# CM41x_M4 register map
Vendor: Analog Devices; Series: CM41x_M4; File version: 1p0
CPU: CM4 r0p1, little endian, MPU, FPU, 4 interrupt priority bits
Registers are 32-bit, read-write, reset 0x0 unless marked. A register's access mark holds for its fields unless they carry their own. Offsets are from the block's base; [hi:lo] are bit positions.

## MATH0 — Math Unit Function
Base 0xF8009000
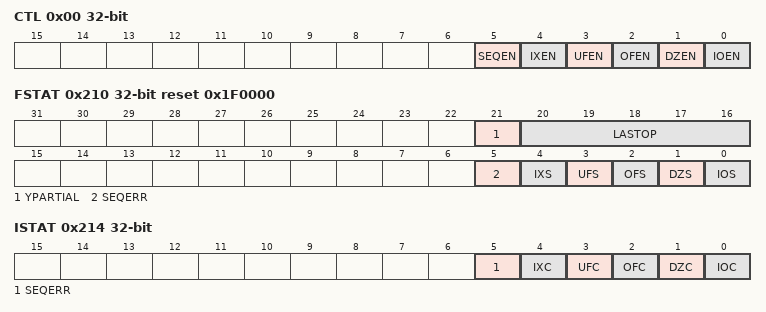
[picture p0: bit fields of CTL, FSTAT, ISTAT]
0x00 CTL — Math Unit Interrupt Enable Control
  [5] SEQEN range 0x00000000..0x00000001 — Interrupt Enable, Sequence Error
  [4] IXEN range 0x00000000..0x00000001 — Interrupt Enable, Inexact Operation
  [3] UFEN range 0x00000000..0x00000001 — Interrupt Enable, Underflow
  [2] OFEN range 0x00000000..0x00000001 — Interrupt Enable, Overflow
  [1] DZEN range 0x00000000..0x00000001 — Interrupt Enable, Divided By Zero
  [0] IOEN range 0x00000000..0x00000001 — Interrupt Enable, Invalid Operation
0x04 EXPF — exp(x) Function Register
  [31:0] DATA range 0x00000000..0xFFFFFFFF — Input Register X
0x0C EXP2F — exp2(x) Function Register
  [31:0] DATA range 0x00000000..0xFFFFFFFF — Input Register X
0x14 RECIPF — Reciprocal(x) or 1/x Function Register
  [31:0] DATA range 0x00000000..0xFFFFFFFF — Input Register X
0x1C SQRTF — Square Root or sqrt(x) Function
  [31:0] DATA range 0x00000000..0xFFFFFFFF — Input Register X
0x24 LNF — ln(x) Function Register
  [31:0] DATA range 0x00000000..0xFFFFFFFF — Input Register X
0x2C LOG2F — log2(x) Function Register
  [31:0] DATA range 0x00000000..0xFFFFFFFF — Input Register X
0x34 SINF — sin(x) Function Register
  [31:0] DATA range 0x00000000..0xFFFFFFFF — Input Register X
0x3C COSF — cos(x) Function Register
  [31:0] DATA range 0x00000000..0xFFFFFFFF — Input Register X
0x44 TANF — tan(x) Function Register
  [31:0] DATA range 0x00000000..0xFFFFFFFF — Input Register X
0x4C ASINF — arcsin(x) Function Register
  [31:0] DATA range 0x00000000..0xFFFFFFFF — Input Register X
0x54 ACOSF — arccos(x) Function Register
  [31:0] DATA range 0x00000000..0xFFFFFFFF — Input Register X
0x5C ATANF — arctan(x) Function Register
  [31:0] DATA range 0x00000000..0xFFFFFFFF — Input Register X
0x80 ATAN2F_Y — arctan(y/x) Function y Operand Register
  [31:0] DATA range 0x00000000..0xFFFFFFFF — Input Register Y
0x84 ATAN2F_X — arctan(y/x) Function x Operand Register
  [31:0] DATA range 0x00000000..0xFFFFFFFF — Input Register X
0x88 HYPOTF_Y — hypot(x,y) Function y Operand Register
  [31:0] DATA range 0x00000000..0xFFFFFFFF — Input Register Y
0x8C HYPOTF_X — hypot(x,y) Function x Operand Register
  [31:0] DATA range 0x00000000..0xFFFFFFFF — Input Register X
0x90 RTOPF_Y — Rectangular to Polar Function y Operand Register
  [31:0] DATA range 0x00000000..0xFFFFFFFF — Input Register Y
0x94 RTOPF_X — Rectangular to Polar Function x Operand Register
  [31:0] DATA range 0x00000000..0xFFFFFFFF — Input Register X
0x98 PTORF_R — Polar to Rectangular Function r Operand Register
  [31:0] DATA range 0x00000000..0xFFFFFFFF — Input Register R
0x9C PTORF_A — Polar to Rectangular Function a Operand Register
  [31:0] DATA range 0x00000000..0xFFFFFFFF — Input Register A
0x200 GY — Generic Y Function Register (GY)
  [31:0] DATA range 0x00000000..0xFFFFFFFF — Input Register Y
0x204 GX — Generic X Function Register (GX)
  [31:0] DATA range 0x00000000..0xFFFFFFFF — Input Register X
0x208 RES1 — Math Unit Function Result 1
  [31:0] DATA range 0x00000000..0xFFFFFFFF — Result Register
0x20C RES2 — Math Unit Function Result 2
  [31:0] DATA range 0x00000000..0xFFFFFFFF — Result Register
0x210 FSTAT reset 0x1F0000 — Math Unit Function Status Register
  [21] YPARTIAL range 0x00000000..0x00000001 — Operand State Status, YPARTIAL register bit
  [20:16] LASTOP — Operand State Status, Last Operand code
    0=EXP (Last operation was EXP.); 1=EXP2 (Last operation was EXP2.); 2=RECIP (Last operation was RECIP.); 3=SQRT (Last operation was SQRT.); 4=LN (Last operation was LN.); 5=LOG2 (Last operation was LOG2.); 6=SIN (Last operation was SIN.); 7=COS (Last operation was COS.); 8=TAN (Last operation was TAN.); 9=ASIN (Last operation was ASIN.); 10=ACOS (Last operation was ACOS.); 11=ATAN (Last operation was ATAN.); 16=ATAN2 (Last operation was ATAN2.); 17=HYPOT (Last operation was HYPOT.); 18=RTOP (Last operation was RTOP.); 19=PTOR (Last operation was PTOR.)
  [5] SEQERR range 0x00000000..0x00000001 — Operand State Status, Sequence Error
  [4] IXS range 0x00000000..0x00000001 — Operand State Status, Inexact Operation
  [3] UFS range 0x00000000..0x00000001 — Operand State Status, Underflow
  [2] OFS range 0x00000000..0x00000001 — Operand State Status, Overflow
  [1] DZS range 0x00000000..0x00000001 — Operand State Status, Divided By Zero
  [0] IOS range 0x00000000..0x00000001 — Operand State Status, Invalid Operation
0x214 ISTAT — Math Unit Interrupt Register
  [5] SEQERR range 0x00000000..0x00000001 — Math Unit Cumulative Interrupt Status, Sequence Error
  [4] IXC range 0x00000000..0x00000001 — Math Unit Cumulative Interrupt Status, Inexact Operation
  [3] UFC range 0x00000000..0x00000001 — Math Unit Cumulative Interrupt Status, Underflow
  [2] OFC range 0x00000000..0x00000001 — Math Unit Cumulative Interrupt Status, Overflow
  [1] DZC range 0x00000000..0x00000001 — Math Unit Cumulative Interrupt Status, Divided By Zero
  [0] IOC range 0x00000000..0x00000001 — Math Unit Cumulative Interrupt Status, Invalid Operation
0x218 SSTAT — Math Unit Function State Status Register
  [0] DIRTY ro — Operand State Status
